# CH569 register map
Vendor: WCH Ltd.; File version: 1.0
CH569 View File
Registers are 32-bit, read-write, reset 0x0 unless marked. A register's access mark holds for its fields unless they carry their own. Offsets are from the block's base; lines under a group give offsets from that group; [hi:lo] are bit positions; {n}, {i} and the like mark numbered series; 'fields as' and 'values as' point back to an identical list; <NAME> marks a mode.

## Memory map
0x40001000 SYS size 0x400
0x40002000 TMR0 size 0x400
0x40002400 TMR1 size 0x400
0x40002800 TMR2 size 0x400
0x40003000 UART0 size 0x400
0x40003400 UART1 size 0x400
0x40003800 UART2 size 0x400
0x40003C00 UART3 size 0x400
0x40004000 SPI0 size 0x400
0x40004400 SPI1 size 0x400
0x40005000 PWMX size 0x400
0x40006000 HSPI size 0x400
0x40007000 ECDC size 0x400
0x40008000 USBSS size 0x400 — USBSS register (Please refer to subprogram library)
0x40009000 USBHS size 0x400
0x4000A000 EMMC size 0x400
0x4000B000 SERDES size 0x400 — SERDES register (Please refer to subprogram library)
0x4000C000 ETH size 0x400 — ETH register (Please refer to subprogram library)
0x4000E000 DVP size 0x400
0xE000E000 PFIC size 0x1000 — Program Fast Interrupt Controller
0xE000F000 Systick size 0x100

## TMR0
Base 0x40002000
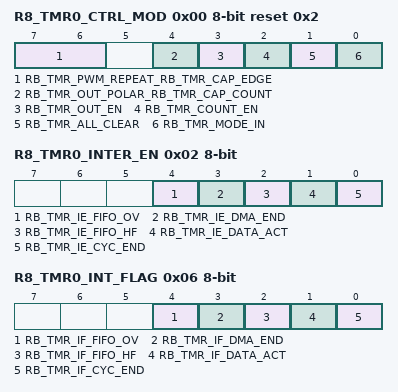
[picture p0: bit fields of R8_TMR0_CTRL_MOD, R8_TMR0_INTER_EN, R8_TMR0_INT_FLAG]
0x00 R8_TMR0_CTRL_MOD 8-bit reset 0x2 — TMR0 mode control
  [7:6] RB_TMR_PWM_REPEAT_RB_TMR_CAP_EDGE — timer PWM repeat mode _ timer capture edge mode
  [4] RB_TMR_OUT_POLAR_RB_TMR_CAP_COUNT — timer PWM output polarity _ Count sub-mode
  [3] RB_TMR_OUT_EN — timer output enable
  [2] RB_TMR_COUNT_EN — timer count enable
  [1] RB_TMR_ALL_CLEAR — force clear timer FIFO and count
  [0] RB_TMR_MODE_IN — timer in mode
0x02 R8_TMR0_INTER_EN 8-bit — TMR0 interrupt enable
  [4] RB_TMR_IE_FIFO_OV — enable interrupt for timer FIFO overflow
  [3] RB_TMR_IE_DMA_END — enable interrupt for timer1/2 DMA completion
  [2] RB_TMR_IE_FIFO_HF — enable interrupt for timer FIFO half (capture fifo >=4 or PWM fifo lower than3)
  [1] RB_TMR_IE_DATA_ACT — enable interrupt for timer capture input action or PWM trigger
  [0] RB_TMR_IE_CYC_END — enable interrupt for timer capture count timeout or PWM cycle end
0x06 R8_TMR0_INT_FLAG 8-bit — TMR0 interrupt flag
  [4] RB_TMR_IF_FIFO_OV — interrupt flag for timer FIFO overflow
  [3] RB_TMR_IF_DMA_END — interrupt flag for timer1/2 DMA completion
  [2] RB_TMR_IF_FIFO_HF — interrupt flag for timer FIFO half (capture fifo >=4 or PWM fifo lower than 3)
  [1] RB_TMR_IF_DATA_ACT — interrupt flag for timer capture input action or PWM trigger
  [0] RB_TMR_IF_CYC_END — interrupt flag for timer capture count timeout or PWM cycle end
0x07 R8_TMR0_FIFO_COUNT 8-bit ro — TMR0 FIFO count status
0x08 R32_TMR0_COUNT ro — TMR0 current count
0x0C R32_TMR0_CNT_END — TMR0 end count value, only low 26 bit
  [31:0] R32_TMR0_COUNT — TMR0 current count
0x10 R32_TMR0_FIFO — TMR0 FIFO register, only low 26 bit
  [31:0] R32_TMR0_FIFO — TMR0 FIFO current count

## TMR1
Base 0x40002400
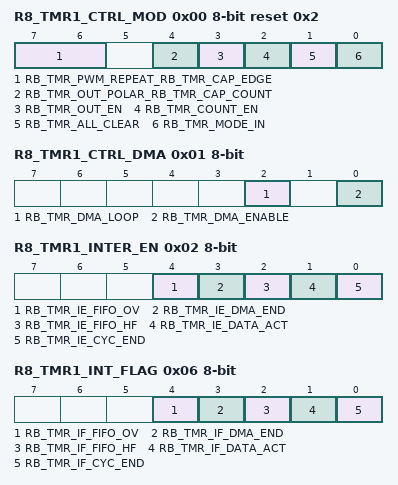
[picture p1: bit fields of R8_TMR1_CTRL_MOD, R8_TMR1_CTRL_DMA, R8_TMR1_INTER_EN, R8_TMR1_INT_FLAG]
0x00 R8_TMR1_CTRL_MOD 8-bit reset 0x2 — TMR1 mode control
  [7:6] RB_TMR_PWM_REPEAT_RB_TMR_CAP_EDGE — timer PWM repeat mode _ timer capture edge mode
  [4] RB_TMR_OUT_POLAR_RB_TMR_CAP_COUNT — timer PWM output polarity _ Count sub-mode
  [3] RB_TMR_OUT_EN — timer output enable
  [2] RB_TMR_COUNT_EN — timer count enable
  [1] RB_TMR_ALL_CLEAR — force clear timer FIFO and count
  [0] RB_TMR_MODE_IN — timer in mode
0x01 R8_TMR1_CTRL_DMA 8-bit — TMR1 DMA control
  [2] RB_TMR_DMA_LOOP — timer1/2 DMA address loop enable
  [0] RB_TMR_DMA_ENABLE — timer1/2 DMA enable
0x02 R8_TMR1_INTER_EN 8-bit — TMR1 interrupt enable
  [4] RB_TMR_IE_FIFO_OV — enable interrupt for timer FIFO overflow
  [3] RB_TMR_IE_DMA_END — enable interrupt for timer1/2 DMA completion
  [2] RB_TMR_IE_FIFO_HF — enable interrupt for timer FIFO half (capture fifo >=4 or PWM fifo lower than3)
  [1] RB_TMR_IE_DATA_ACT — enable interrupt for timer capture input action or PWM trigger
  [0] RB_TMR_IE_CYC_END — enable interrupt for timer capture count timeout or PWM cycle end
0x06 R8_TMR1_INT_FLAG 8-bit — TMR1 interrupt flag
  [4] RB_TMR_IF_FIFO_OV — interrupt flag for timer FIFO overflow
  [3] RB_TMR_IF_DMA_END — interrupt flag for timer1_2 DMA completion
  [2] RB_TMR_IF_FIFO_HF — interrupt flag for timer FIFO half (capture fifo >=4 or PWM fifo lower than 3)
  [1] RB_TMR_IF_DATA_ACT — interrupt flag for timer capture input action or PWM trigger
  [0] RB_TMR_IF_CYC_END — interrupt flag for timer capture count timeout or PWM cycle end
0x07 R8_TMR1_FIFO_COUNT 8-bit ro — TMR1 FIFO count status
  [7:0] R8_TMR1_FIFO_COUNT — TMR FIFO count status
0x08 R32_TMR1_COUNT ro — TMR1 current count
  [31:0] R32_TMR1_COUNT — TMR current count
0x0C R32_TMR1_CNT_END — TMR1 end count value, only low 26 bit
  [31:0] R32_TMR1_CNT_END — TMR current count
0x10 R32_TMR1_FIFO — TMR1 FIFO only low 26 bit
  [31:0] R32_TMR1_FIFO — TMR current count
0x14 R32_TMR1_DMA_NOW — TMR1 DMA current address
  [17:0] R16_TMR1_DMA_NOW — TMR DMA current address
0x18 R32_TMR1_DMA_BEG — TMR1 DMA begin address
  [17:0] R16_TMR1_DMA_BEG
0x1C R32_TMR1_DMA_END — TMR1 DMA end address
  [17:0] R16_TMR1_DMA_END
